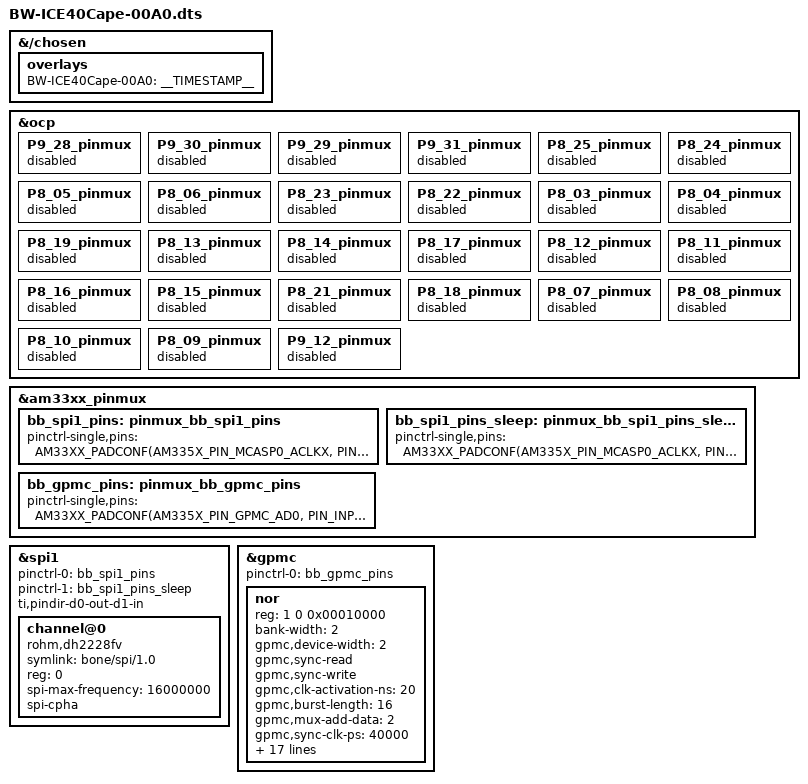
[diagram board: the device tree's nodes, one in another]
/*
 * Copyright (C) 2021 Omkar Bhilare <ombhilare999@gmail.com>
 * See Cape Interface Spec page for more info on Bone Buses
 *
 * This program is free software; you can redistribute it and/or modify
 * it under the terms of the GNU General Public License version 2 as
 * published by the Free Software Foundation.
 */

/dts-v1/;
/plugin/;

#include <dt-bindings/gpio/gpio.h>
#include <dt-bindings/pinctrl/am33xx.h>

/*
* Helper to show loaded overlays under: /proc/device-tree/chosen/overlays/
*/
&{/chosen} {
    overlays {
        BW-ICE40Cape-00A0 = __TIMESTAMP__;
    };
};

/*
 * Free up the pins used by the cape from the pinmux helpers.
 */
&ocp {
	P9_28_pinmux { status = "disabled"; };	/* P9_28 (C12) mcasp0_ahclkr.spi1_cs0 */
	P9_30_pinmux { status = "disabled"; };	/* P9_30 (D12) mcasp0_axr0.spi1_d1 */
	P9_29_pinmux { status = "disabled"; };	/* P9_29 (B13) mcasp0_fsx.spi1_d0 */
	P9_31_pinmux { status = "disabled"; };	/* P9_31 (A13) mcasp0_aclkx.spi1_sclk */

    P8_25_pinmux { status = "disabled"; }; /* bw_gpmc_ad0 */
    P8_24_pinmux { status = "disabled"; }; /* bw_gpmc_ad1 */
    P8_05_pinmux { status = "disabled"; }; /* bw_gpmc_ad2 */
    P8_06_pinmux { status = "disabled"; }; /* bw_gpmc_ad3 */
    P8_23_pinmux { status = "disabled"; }; /* bw_gpmc_ad4 */
    P8_22_pinmux { status = "disabled"; }; /* bw_gpmc_ad5 */
    P8_03_pinmux { status = "disabled"; }; /* bw_gpmc_ad6 */
    P8_04_pinmux { status = "disabled"; }; /* bw_gpmc_ad7 */
    P8_19_pinmux { status = "disabled"; }; /* bw_gpmc_ad8 */
    P8_13_pinmux { status = "disabled"; }; /* bw_gpmc_ad9 */
    P8_14_pinmux { status = "disabled"; }; /* bw_gpmc_ad10 */
    P8_17_pinmux { status = "disabled"; }; /* bw_gpmc_ad11*/
    P8_12_pinmux { status = "disabled"; }; /* bw_gpmc_ad12 */
    P8_11_pinmux { status = "disabled"; }; /* bw_gpmc_ad13 */
    P8_16_pinmux { status = "disabled"; }; /* bw_gpmc_ad14 */
    P8_15_pinmux { status = "disabled"; }; /* bw_gpmc_ad15 */
    P8_21_pinmux { status = "disabled"; }; /* bw_gpmc_csn1 */
    P8_18_pinmux { status = "disabled"; }; /* bw_gpmc_clk  */
    P8_07_pinmux { status = "disabled"; }; /* bw_gpmc_advn_ale */
    P8_08_pinmux { status = "disabled"; }; /* bw_gpmc_oen_ren */
    P8_10_pinmux { status = "disabled"; }; /* bw_gpmc_wen */
    P8_09_pinmux { status = "disabled"; }; /* bw_gpmc_be0n_cle*/
    P9_12_pinmux { status = "disabled"; }; /* bw_gpmc_be1n */
};

&am33xx_pinmux {
	bb_spi1_pins: pinmux_bb_spi1_pins {
		pinctrl-single,pins = <
			AM33XX_PADCONF(AM335X_PIN_MCASP0_ACLKX, PIN_OUTPUT_PULLUP | INPUT_EN, MUX_MODE3)	/* P9_31 (A13) mcasp0_aclkx.spi1_sclk */
			AM33XX_PADCONF(AM335X_PIN_MCASP0_FSX, PIN_OUTPUT_PULLUP | INPUT_EN, MUX_MODE3)	/* P9_29 (B13) mcasp0_fsx.spi1_d0 */
			AM33XX_PADCONF(AM335X_PIN_MCASP0_AXR0, PIN_OUTPUT_PULLUP | INPUT_EN, MUX_MODE3)	/* P9_30 (D12) mcasp0_axr0.spi1_d1 */
			AM33XX_PADCONF(AM335X_PIN_MCASP0_AHCLKR, PIN_OUTPUT_PULLUP | INPUT_EN, MUX_MODE3)	/* P9_28 (C12) mcasp0_ahclkr.spi1_cs0 */
		>;
	};

	bb_spi1_pins_sleep: pinmux_bb_spi1_pins_sleep {
		pinctrl-single,pins = <
			AM33XX_PADCONF(AM335X_PIN_MCASP0_ACLKX, PIN_INPUT, MUX_MODE7)	/* P9_31 (A13) mcasp0_aclkx.spi1_sclk */
			AM33XX_PADCONF(AM335X_PIN_MCASP0_FSX, PIN_INPUT, MUX_MODE7)	/* P9_29 (B13) mcasp0_fsx.spi1_d0 */
			AM33XX_PADCONF(AM335X_PIN_MCASP0_AXR0, PIN_INPUT, MUX_MODE7)	/* P9_30 (D12) mcasp0_axr0.spi1_d1 */
			AM33XX_PADCONF(AM335X_PIN_MCASP0_AHCLKR, PIN_INPUT, MUX_MODE7)	/* P9_28 (C12) mcasp0_ahclkr.spi1_cs0 */
		>;
	};

	bb_gpmc_pins: pinmux_bb_gpmc_pins {
		pinctrl-single,pins = <
			AM33XX_PADCONF(AM335X_PIN_GPMC_AD0, PIN_INPUT_PULLUP, MUX_MODE0)
			AM33XX_PADCONF(AM335X_PIN_GPMC_AD1, PIN_INPUT_PULLUP, MUX_MODE0)
			AM33XX_PADCONF(AM335X_PIN_GPMC_AD2, PIN_INPUT_PULLUP, MUX_MODE0)
			AM33XX_PADCONF(AM335X_PIN_GPMC_AD3, PIN_INPUT_PULLUP, MUX_MODE0)
			AM33XX_PADCONF(AM335X_PIN_GPMC_AD4, PIN_INPUT_PULLUP, MUX_MODE0)
			AM33XX_PADCONF(AM335X_PIN_GPMC_AD5, PIN_INPUT_PULLUP, MUX_MODE0)
			AM33XX_PADCONF(AM335X_PIN_GPMC_AD6, PIN_INPUT_PULLUP, MUX_MODE0)
			AM33XX_PADCONF(AM335X_PIN_GPMC_AD7, PIN_INPUT_PULLUP, MUX_MODE0)
			AM33XX_PADCONF(AM335X_PIN_GPMC_AD8, PIN_INPUT_PULLUP, MUX_MODE0)
			AM33XX_PADCONF(AM335X_PIN_GPMC_AD9, PIN_INPUT_PULLUP, MUX_MODE0)
			AM33XX_PADCONF(AM335X_PIN_GPMC_AD10, PIN_INPUT_PULLUP, MUX_MODE0)
			AM33XX_PADCONF(AM335X_PIN_GPMC_AD11, PIN_INPUT_PULLUP, MUX_MODE0)
			AM33XX_PADCONF(AM335X_PIN_GPMC_AD12, PIN_INPUT_PULLUP, MUX_MODE0)
			AM33XX_PADCONF(AM335X_PIN_GPMC_AD13, PIN_INPUT_PULLUP, MUX_MODE0)
			AM33XX_PADCONF(AM335X_PIN_GPMC_AD14, PIN_INPUT_PULLUP, MUX_MODE0)
			AM33XX_PADCONF(AM335X_PIN_GPMC_AD15, PIN_INPUT_PULLUP, MUX_MODE0)

			AM33XX_PADCONF(AM335X_PIN_GPMC_CLK, PIN_INPUT, MUX_MODE0)

			AM33XX_PADCONF(AM335X_PIN_GPMC_CSN1, PIN_OUTPUT, MUX_MODE0)
			AM33XX_PADCONF(AM335X_PIN_GPMC_ADVN_ALE, PIN_OUTPUT, MUX_MODE0)
			AM33XX_PADCONF(AM335X_PIN_GPMC_OEN_REN, PIN_OUTPUT, MUX_MODE0)
			AM33XX_PADCONF(AM335X_PIN_GPMC_WEN, PIN_OUTPUT, MUX_MODE0)
			AM33XX_PADCONF(AM335X_PIN_GPMC_BEN0_CLE, PIN_OUTPUT, MUX_MODE0)
			AM33XX_PADCONF(AM335X_PIN_GPMC_BEN1, PIN_OUTPUT, MUX_MODE0)
		>;
	};
};

&spi1 {
	#address-cells = <1>;
	#size-cells = <0>;

	status = "okay";
	pinctrl-names = "default", "sleep";
	pinctrl-0 = <&bb_spi1_pins>;
	pinctrl-1 = <&bb_spi1_pins_sleep>;

	/*
	 * Select the D0 pin as output and D1 as
	 * input. The default is D0 as input and
	 * D1 as output.
	 */
	ti,pindir-d0-out-d1-in;

	channel@0 {
		#address-cells = <1>;
		#size-cells = <0>;

		compatible = "rohm,dh2228fv";
		symlink = "bone/spi/1.0";

		reg = <0>;
		spi-max-frequency = <16000000>;
		spi-cpha;
    };
};

&gpmc{
    status = "okay";

	pinctrl-names = "default";
	pinctrl-0 = <&bb_gpmc_pins>;

    /* chip select ranges */
    ranges = <
        1 0 0x01000000 0x01000000>;

    nor {
        reg = <1 0 0x00010000>;         /*CSn1*/
        bank-width = <2>;               /* GPMC_CONFIG1_DEVICESIZE(1) */

        gpmc,device-width = <2>;

        /*gpmc,burst-write;
        gpmc,burst-read;
        gpmc,burst-wrap;*/
        gpmc,sync-read;                 /* GPMC_CONFIG1_READTYPE_ASYNC */
        gpmc,sync-write;                /* GPMC_CONFIG1_WRITETYPE_ASYNC */
        gpmc,clk-activation-ns = <20>;   /* GPMC_CONFIG1_CLKACTIVATIONTIME(2) */
        gpmc,burst-length = <16>;       /* GPMC_CONFIG1_PAGE_LEN(2) */
        gpmc,mux-add-data = <2>;        /* GPMC_CONFIG1_MUXTYPE(2) */

        /* CONFIG2 */
        gpmc,sync-clk-ps = <40000>;
        gpmc,cs-on-ns = <0>;
        gpmc,cs-rd-off-ns = <120>;
        gpmc,cs-wr-off-ns = <80>;

        /* CONFIG3 */
        gpmc,adv-on-ns = <0>;
        gpmc,adv-rd-off-ns = <40>;
        gpmc,adv-wr-off-ns = <40>;

        /* CONFIG4 */
        gpmc,we-on-ns = <40>;
        gpmc,we-off-ns = <80>;
        gpmc,oe-on-ns = <40>;
        gpmc,oe-off-ns = <120>;

        /* CONFIG 5 */
        gpmc,page-burst-access-ns = <40>;
        gpmc,access-ns = <160>;
        gpmc,rd-cycle-ns = <180>;
        gpmc,wr-cycle-ns = <100>;

        /* CONFIG 6 */
        gpmc,wr-access-ns = <80>;
        gpmc,wr-data-mux-bus-ns = <40>;
        gpmc,bus-turnaround-ns = <40>;  /* CONFIG6:3:0 = 4 */
        /*gpmc,cycle2cycle-samecsen;*/      /* CONFIG6:7 = 1 */
        /*gpmc,cycle2cycle-delay-ns = <40>;*/   /* CONFIG6:11:8 = 4 */
    };
};
